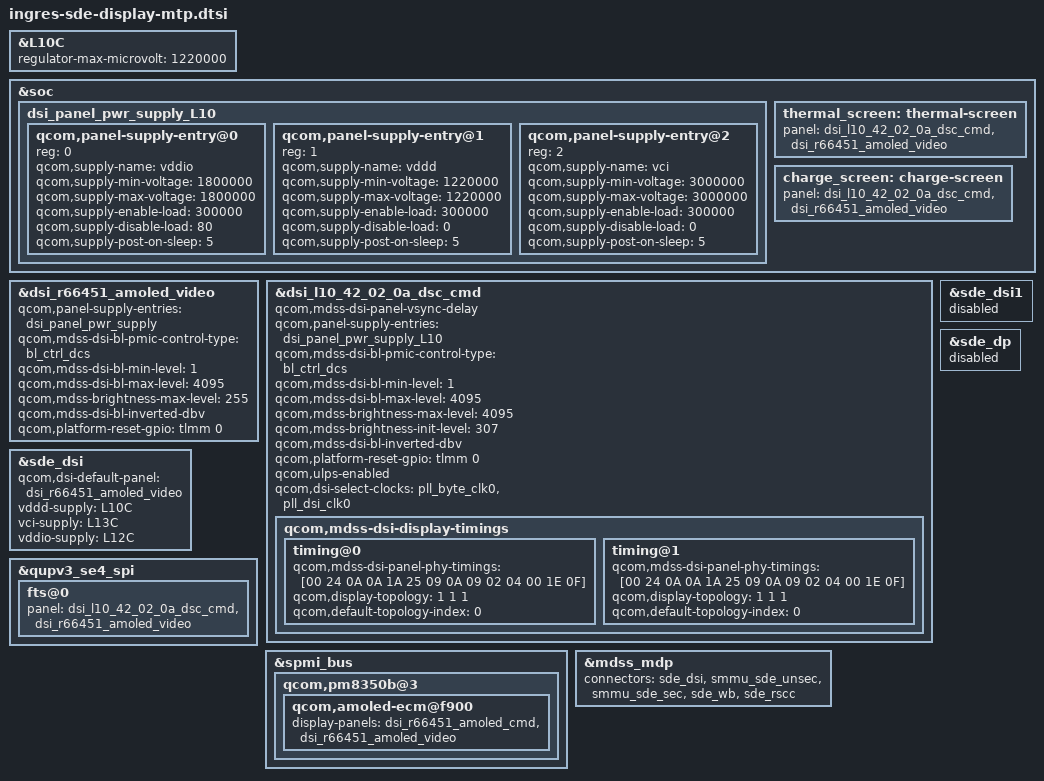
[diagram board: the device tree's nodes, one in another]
#include "waipio-sde-display.dtsi"
#include "dsi-panel-l10-42-02-0a-dsc-cmd.dtsi"

&L10C {
	regulator-max-microvolt = <1220000>;
};

&soc {
	dsi_panel_pwr_supply_L10: dsi_panel_pwr_supply_L10 {
		#address-cells = <1>;
		#size-cells = <0>;
		qcom,panel-supply-entry@0 {
			reg = <0>;
			qcom,supply-name = "vddio";
			qcom,supply-min-voltage = <1800000>;
			qcom,supply-max-voltage = <1800000>;
			qcom,supply-enable-load = <300000>;
			qcom,supply-disable-load = <80>;
			qcom,supply-post-on-sleep = <5>;
		};
		qcom,panel-supply-entry@1 {
			reg = <1>;
			qcom,supply-name = "vddd";
			qcom,supply-min-voltage = <1220000>;
			qcom,supply-max-voltage = <1220000>;
			qcom,supply-enable-load = <300000>;
			qcom,supply-disable-load = <0>;
			qcom,supply-post-on-sleep = <5>;
		};
		qcom,panel-supply-entry@2 {
			reg = <2>;
			qcom,supply-name = "vci";
			qcom,supply-min-voltage = <3000000>;
			qcom,supply-max-voltage = <3000000>;
			qcom,supply-enable-load = <300000>;
			qcom,supply-disable-load = <0>;
			qcom,supply-post-on-sleep = <5>;
		};
	};
};

&dsi_r66451_amoled_video {
	qcom,panel-supply-entries = <&dsi_panel_pwr_supply>;
	qcom,mdss-dsi-bl-pmic-control-type = "bl_ctrl_dcs";
	qcom,mdss-dsi-bl-min-level = <1>;
	qcom,mdss-dsi-bl-max-level = <4095>;
	qcom,mdss-brightness-max-level = <255>;
	qcom,mdss-dsi-bl-inverted-dbv;
	qcom,platform-reset-gpio = <&tlmm 0 0>;
};

&dsi_l10_42_02_0a_dsc_cmd {
	qcom,mdss-dsi-panel-vsync-delay;
	qcom,panel-supply-entries = <&dsi_panel_pwr_supply_L10>;
	qcom,mdss-dsi-bl-pmic-control-type = "bl_ctrl_dcs";
	qcom,mdss-dsi-bl-min-level = <1>;
	qcom,mdss-dsi-bl-max-level = <4095>;
	qcom,mdss-brightness-max-level = <4095>;
	qcom,mdss-brightness-init-level = <307>;
	qcom,mdss-dsi-bl-inverted-dbv;
	qcom,platform-reset-gpio = <&tlmm 0 0>;
};

&dsi_l10_42_02_0a_dsc_cmd {
	qcom,ulps-enabled;
	qcom,dsi-select-clocks = "pll_byte_clk0", "pll_dsi_clk0";
		qcom,mdss-dsi-display-timings {
		/* 60 Hz */
		timing@0{
			qcom,mdss-dsi-panel-phy-timings = [00 24 0A 0A 1A 25 09
				0A 09 02 04 00 1E 0F];
			qcom,display-topology = <1 1 1>;
			qcom,default-topology-index = <0>;
		};
		/*120 Hz*/
		timing@1{
			qcom,mdss-dsi-panel-phy-timings = [00 24 0A 0A 1A 25 09
				0A 09 02 04 00 1E 0F];
			qcom,display-topology = <1 1 1>;
			qcom,default-topology-index = <0>;
		};
	};
};

&sde_dsi {
	qcom,dsi-default-panel = <&dsi_r66451_amoled_video>;
	vddd-supply = <&L10C>;
	vci-supply = <&L13C>;
	vddio-supply = <&L12C>;
};

&qupv3_se4_spi {
	fts@0 {
		panel = <&dsi_l10_42_02_0a_dsc_cmd
			&dsi_r66451_amoled_video>;
	};
};

&spmi_bus {
	qcom,pm8350b@3 {
		qcom,amoled-ecm@f900 {
			display-panels = <&dsi_r66451_amoled_cmd
					&dsi_r66451_amoled_video>;
		};
	};
};

&sde_dsi1 {
	status = "disabled";
};

&sde_dp {
	status = "disabled";
};

&mdss_mdp {
	connectors = <&sde_dsi &smmu_sde_unsec &smmu_sde_sec &sde_wb &sde_rscc>;
};

&soc {
	thermal_screen: thermal-screen {
		panel = <&dsi_l10_42_02_0a_dsc_cmd
			&dsi_r66451_amoled_video>;
        };
	charge_screen: charge-screen {
		panel = <&dsi_l10_42_02_0a_dsc_cmd
			&dsi_r66451_amoled_video>;
	};
};
